# SN32F770 register map
Vendor: SONiX Technology Co., Ltd.; Series: SN32F770; File version: 1.4
CPU: CM0 r0p0, little endian, no MPU, no FPU, 2 interrupt priority bits
Registers are 32-bit, read-write, reset 0x0 unless marked. A register's access mark holds for its fields unless they carry their own. Offsets are from the block's base; [hi:lo] are bit positions.

## SN_CMP — Comparator
Base 0x40028000
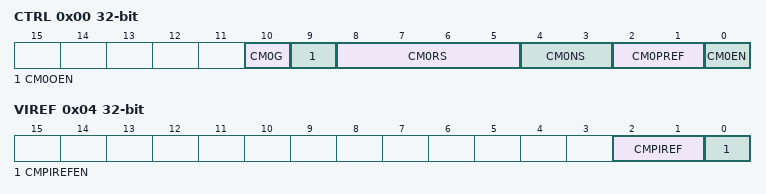
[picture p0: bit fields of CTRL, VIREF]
0x00 CTRL — Offset:0x00 CMP Control Register
  [10] CM0G — CMP0 interrupt trigger direction control bit
    0=Falling range trigger (CMP0 output status is from high to low as VPREF0 less than CM0N); 1=Rising edge trigger (CMP0 output status is from low to high as VPREF0 more than CM0N)
  [9] CM0OEN — CMP0 Output pin control bit
    0=Disable CM0O; 1=Enable CM0O
  [8:5] CM0RS — CMP0 internal reference voltage (VIREF0) selection bits
    0=0000b (VIREF0=VIREF); 1=0001b (VIREF0=VIREF*1/16); 2=0010b (VIREF0=VIREF*2/16); 3=0011b (VIREF0=VIREF*3/16); 4=0100b (VIREF0=VIREF*4/16); 5=0101b (VIREF0=VIREF*5/16); 6=0110b (VIREF0=VIREF*6/16); 7=0111b (VIREF0=VIREF*7/16); 8=1000b (VIREF0=VIREF*8/16); 9=1001b (VIREF0=VIREF*9/16); 10=1010b (VIREF0=VIREF*10/16); 11=1011b (VIREF0=VIREF*11/16); 12=1100b (VIREF0=VIREF*12/16); 13=1101b (VIREF0=VIREF*13/16); 14=1110b (VIREF0=VIREF*14/16); 15=1111b (VIREF0=VIREF*15/16)
  [4:3] CM0NS — CMP0 negative input pin selection bit
    0=CM0N0 (CM0N0 is comparator negative input pin, and isolate GPIO function); 1=CM0N1 (CM0N1 is comparator negative input pin, and isolate GPIO function); 2=CM0N2 (CM0N2 is comparator negative input pin, and isolate GPIO function)
  [2:1] CM0PREF — CMP0 Positive reference voltage (VPREF0) source
    0=VIREF0 (VIREF0. CM0P0/CM0P1/CM0P2 pins are GPIO mode.); 1=CM0P0 (CM0P0 is comparator positive input pin, and isolate GPIO function); 2=CM0P1 (CM0P1 is comparator positive input pin, and isolate GPIO function); 3=CM0P2 (CM0P2 is comparator positive input pin, and isolate GPIO function)
  [0] CM0EN — CMP0 Enable bit
    0=Disable CMP0; 1=Enable CMP0
0x04 VIREF — Offset:0x04 CMP Internal Reference Voltage register
  [2:1] CMPIREF — CMP internal reference voltage (VIREF) source
    3=VDD (VIREF=VDD); 2=Internal 1P5V (VIREF=Internal 1P5V); 1=Internal 2V (VIREF=Internal 2V); 0=Internal 3V (VIREF=Internal 3V)
  [0] CMPIREFEN — CMP internal reference voltage (VIREF) enable
    0=Disable CMP internal reference voltage; 1=Enable CMP internal reference voltage
0x08 OS ro — Offset:0x08 CMP Output Status Register
  [0] CM0OUT — CMP0 Output flag bit
    0=CMP0 positive voltage is less than CM0N voltage (VPREF0 is less than CM0N voltage); 1=CMP0 positive voltage is more than CM0N voltage (VPREF0 is more than CM0N voltage)
0x0C IE — Offset:0x0C CMP Interrupt Enable Register
  [0] CM0IE — CMP0 interrupt enable
    0=Disable CMP0 interrupt; 1=Enable CMP0 interrupt
0x10 RIS ro — Offset:0x10 CMP n Raw Interrupt Status Register
  [0] CM0IF — CMP0 raw interrupt flag
    0=No interrupt on CMP0; 1=Met interrupt requirements (Interrupt requirements met on CMP0)
0x14 IC wo — Offset:0x14 CMP Interrupt Clear Register
  [0] CM0IC — CMP0 interrupt flag clear bit
    0=No effect; 1=Clear CMP0 interrupt flag
0x18 DB — Offset:0x18 CMP Interrupt Clear Register
  [2:0] CM0DB — Count for CMP0 output debounce time
    0=000b (Disable CMP0 output debounce circuit); 1=001b (CMP0 output debounce time = 2*CMP0_PCLK); 2=010b (CMP0 output debounce time = 4*CMP0_PCLK); 3=011b (CMP0 output debounce time = 8*CMP0_PCLK); 4=100b (CMP0 output debounce time = 16*CMP0_PCLK); 5=101b (CMP0 output debounce time = 32*CMP0_PCLK); 6=110b (CMP0 output debounce time = 64*CMP0_PCLK); 7=111b (CMP0 output debounce time = 128*CMP0_PCLK)

## SN_WDT — Watchdog Timer
Base 0x40010000
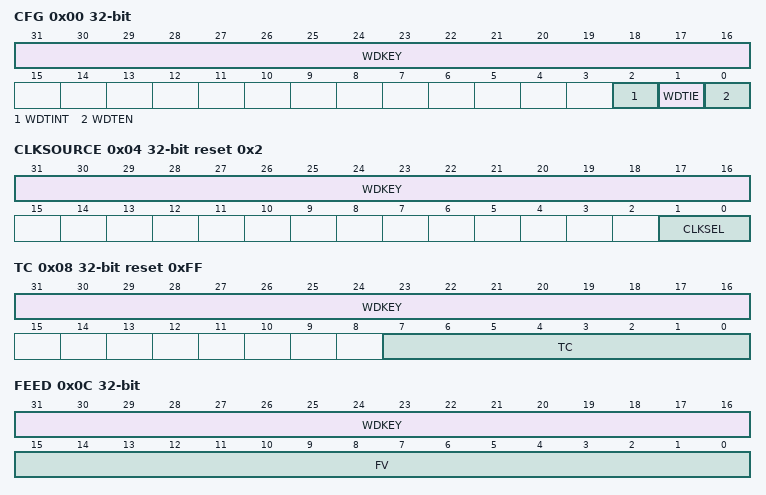
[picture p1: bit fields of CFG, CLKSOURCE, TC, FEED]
0x00 CFG — Offset:0x00 WDT Configuration Register
  [31:16] WDKEY wo — WDT register key
  [2] WDTINT — WDT interrupt flag
    0=No (No WDT time-out); 1=WDT time-out (WDT interrupt is triggered if WDTIE=1)
  [1] WDTIE — WDT interrupt enable
    0=Disable (WDT reset when WDT time-out); 1=Enable WDT interrupt
  [0] WDTEN — WDT enable
    0=Disable WDT; 1=Enable WDT
0x04 CLKSOURCE reset 0x2 (reset mask 0xFFFF0002) — Offset:0x04 WDT Clock Source Register
  [31:16] WDKEY wo — WDT register key
  [1:0] CLKSEL — WDT clock source
    2=ILRC (WDT clock source=ILRC)
0x08 TC reset 0xFF — Offset:0x08 WDT Timer Constant Register
  [31:16] WDKEY wo — WDT register key
  [7:0] TC — Watchdog timer constant reload value
0x0C FEED wo — Offset:0x0C WDT Feed Register
  [31:16] WDKEY — WDT register key
  [15:0] FV — Watchdog feed value

## SN_FLASH — FLASH Memory Control Registers
Base 0x40062000
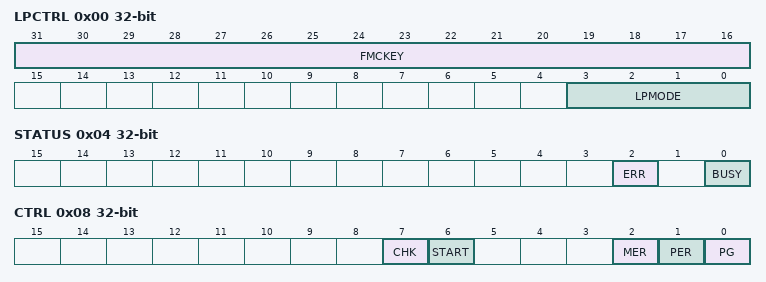
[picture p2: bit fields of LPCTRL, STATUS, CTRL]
0x00 LPCTRL — Offset:0x00 Flash Low Power Control Register
  [31:16] FMCKEY wo — FMC verify key
  [3:0] LPMODE — Flash Low Power mode selection bit
    0=0000b (HCLK is less than or equal to 12MHz); 3=0011b (HCLK is more than 12MHz, and less than or equal to 24MHz); 5=0101b (HCLK is more than 24MHz)
0x04 STATUS — Offset:0x04 Flash Status Register
  [2] ERR — Erase/Error flag
    0=No error; 1=Error (The address is illegal or over page boundary)
  [0] BUSY ro — Busy flag
    0=Idle (FMC is idle); 1=Busy (Flash operation is in process)
0x08 CTRL — Offset:0x08 Flash Control Register
  [7] CHK — Checksum calculation chosen
    0=Disable; 1=Enable (Trigger checksum calculation)
  [6] START — Start erase/program operation
    0=Stop/finish operation; 1=Start erase/program operation
  [2] MER — Mass erase mode chosen bit
    0=Disable masse erase mode; 1=Enable mass erase mode
  [1] PER — Page erase mode chosen bit
    0=Disable page erase mode; 1=Enable page erase mode
  [0] PG — Flash program mode chosen bit
    0=Disable Flash program mode; 1=Enable Flash program mode
0x0C DATA — Offset:0x0C Flash Data Register
  [31:0] DATA — Data to be programmed or be read
0x10 ADDR — Offset:0x10 Flash Address Register
  [31:0] ADDR — Flash Address
0x14 CHKSUM ro — Offset:0x14 Flash Checksum Register
  [15:0] UserROM — Checksum of User ROM

## SN_UC — UC Registers
Base 0x1FFF2224
0x00 L4BYTE ro — Offset:0x00 UC Low 4 Byte Register
0x04 H4BYTE ro — Offset:0x04 UC High 4 Byte Register
